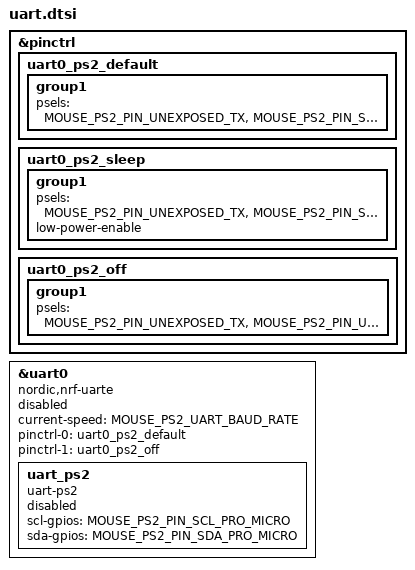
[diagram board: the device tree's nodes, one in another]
&pinctrl {
	// This pinctrl state is used for receiving
	// For `UART_TX`, set an unused and unexposed pin
	// For `UART_RX`, set the PS/2 SDA pin number
	uart0_ps2_default: uart0_ps2_default {
		group1 {
			psels = MOUSE_PS2_PIN_UNEXPOSED_TX,
					MOUSE_PS2_PIN_SDA_PINCTRL;
		};
	};
	// Set this to the same pins as uart0_ps2_default
	uart0_ps2_sleep: uart0_ps2_sleep {
		group1 {
			psels = MOUSE_PS2_PIN_UNEXPOSED_TX,
					MOUSE_PS2_PIN_SDA_PINCTRL;
			low-power-enable;
		};
	};
	// The nrf52 UART controller is not compatible with the PS/2
	// transmission frame. So the PS/2 UART driver doesn't use UART for
	// transmissions and instead use GPIO bit-banging.
	//
	// When the driver switches to transmit mode, it frees up the SDA pin by
    // switching the UART controller to unexposed/unused pins.
	//
	// Then it configures the GPIO controller to use the SCL and SDA pins
	uart0_ps2_off: uart0_ps2_off {
		group1 {
			psels = MOUSE_PS2_PIN_UNEXPOSED_TX,
					MOUSE_PS2_PIN_UNEXPOSED_RX;
		};
	};
};

&uart0 {
	status = "disabled";
	compatible = "nordic,nrf-uarte";
	current-speed = MOUSE_PS2_UART_BAUD_RATE;
	pinctrl-0 = <&uart0_ps2_default>;
	pinctrl-1 = <&uart0_ps2_off>;
	pinctrl-names = "default", "sleep";
	uart_ps2: uart_ps2 {
		status = "disabled";
		compatible = "uart-ps2";
		scl-gpios = MOUSE_PS2_PIN_SCL_PRO_MICRO;
		sda-gpios = MOUSE_PS2_PIN_SDA_PRO_MICRO;
	};
};
